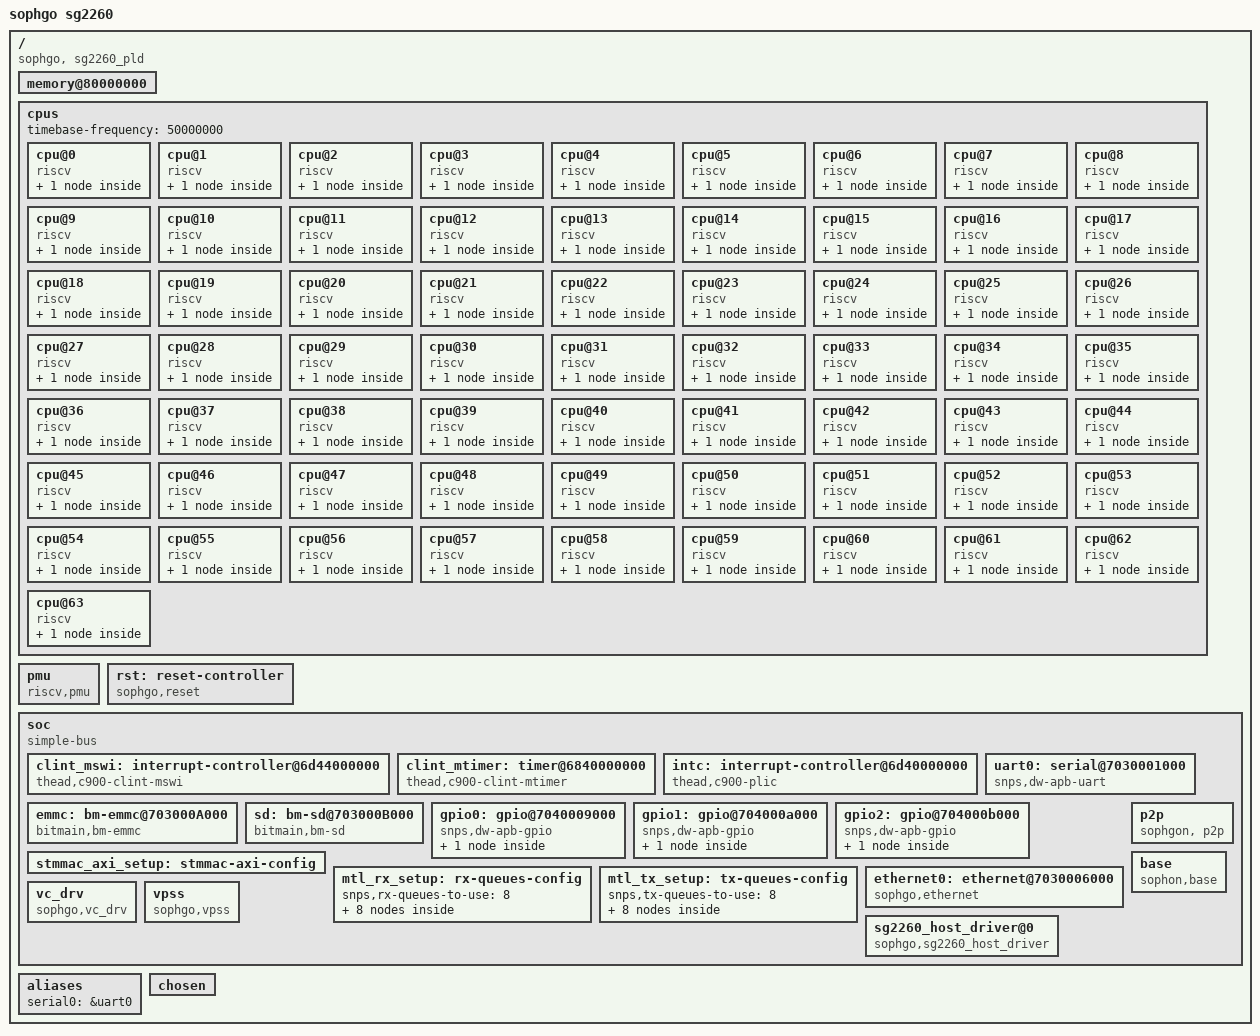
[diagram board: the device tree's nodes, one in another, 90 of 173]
// SPDX-License-Identifier: (GPL-2.0 OR MIT)
/*
 * Copyright (C) 2022 Sophgo Technology Inc. All rights reserved.
 */

/dts-v1/;
#include <dt-bindings/interrupt-controller/irq.h>
#include <dt-bindings/clock/sophgo,sg2044-clock.h>
#include <dt-bindings/reset/sophgo,sg2044-reset.h>
#include "sg2044-clock.dtsi"
#include "sg2044-pinctrl.dtsi"

/ {
	model = "sophgo sg2260";
	compatible = "sophgo, sg2260_pld";
	#address-cells = <2>;
	#size-cells = <2>;
	dma-noncoherent;

	memory@80000000 {
		device_type = "memory";
		reg = <0x00000000 0x80000000 0x00000010 0x00000000>;
	};

	cpus {
		#address-cells = <1>;
		#size-cells = <0>;
		timebase-frequency = <50000000>;
		cpu@0 {
			device_type = "cpu";
			reg = <0>;
			status = "okay";
			compatible = "riscv";
			riscv,isa = "rv64imafdcv_zicbom_zicbop_zicboz_zicond1p0_zihintntl0p2_zihintpause_zawrs_zfa0p1_zfbfmin0p8_zfh_zca_zcb_zcd_zba_zbb_zbc_zbs_zvfbfmin0p8_zvfbfwma0p8_zvfh0p1_sscofpmf_sstc_svinval_svnapot_svpbmt";
			riscv,cbom-block-size = <64>;
			riscv,cboz-block-size = <64>;
			mmu-type = "riscv,sv48";
			cpu0_intc: interrupt-controller {
				#interrupt-cells = <1>;
				compatible = "riscv,cpu-intc";
				interrupt-controller;
			};
		};
		cpu@1 {
			device_type = "cpu";
			reg = <1>;
			status = "okay";
			compatible = "riscv";
			riscv,isa = "rv64imafdcv_zicbom_zicbop_zicboz_zicond1p0_zihintntl0p2_zihintpause_zawrs_zfa0p1_zfbfmin0p8_zfh_zca_zcb_zcd_zba_zbb_zbc_zbs_zvfbfmin0p8_zvfbfwma0p8_zvfh0p1_sscofpmf_sstc_svinval_svnapot_svpbmt";
			riscv,cbom-block-size = <64>;
			riscv,cboz-block-size = <64>;
			mmu-type = "riscv,sv48";
			cpu1_intc: interrupt-controller {
				#interrupt-cells = <1>;
				compatible = "riscv,cpu-intc";
				interrupt-controller;
			};
		};
		cpu@2 {
			device_type = "cpu";
			reg = <2>;
			status = "okay";
			compatible = "riscv";
			riscv,isa = "rv64imafdcv_zicbom_zicbop_zicboz_zicond1p0_zihintntl0p2_zihintpause_zawrs_zfa0p1_zfbfmin0p8_zfh_zca_zcb_zcd_zba_zbb_zbc_zbs_zvfbfmin0p8_zvfbfwma0p8_zvfh0p1_sscofpmf_sstc_svinval_svnapot_svpbmt";
			riscv,cbom-block-size = <64>;
			riscv,cboz-block-size = <64>;
			mmu-type = "riscv,sv48";
			cpu2_intc: interrupt-controller {
				#interrupt-cells = <1>;
				compatible = "riscv,cpu-intc";
				interrupt-controller;
			};
		};
		cpu@3 {
			device_type = "cpu";
			reg = <3>;
			status = "okay";
			compatible = "riscv";
			riscv,isa = "rv64imafdcv_zicbom_zicbop_zicboz_zicond1p0_zihintntl0p2_zihintpause_zawrs_zfa0p1_zfbfmin0p8_zfh_zca_zcb_zcd_zba_zbb_zbc_zbs_zvfbfmin0p8_zvfbfwma0p8_zvfh0p1_sscofpmf_sstc_svinval_svnapot_svpbmt";
			riscv,cbom-block-size = <64>;
			riscv,cboz-block-size = <64>;
			mmu-type = "riscv,sv48";
			cpu3_intc: interrupt-controller {
				#interrupt-cells = <1>;
				compatible = "riscv,cpu-intc";
				interrupt-controller;
			};
		};
		cpu@4 {
			device_type = "cpu";
			reg = <4>;
			status = "okay";
			compatible = "riscv";
			riscv,isa = "rv64imafdcv_zicbom_zicbop_zicboz_zicond1p0_zihintntl0p2_zihintpause_zawrs_zfa0p1_zfbfmin0p8_zfh_zca_zcb_zcd_zba_zbb_zbc_zbs_zvfbfmin0p8_zvfbfwma0p8_zvfh0p1_sscofpmf_sstc_svinval_svnapot_svpbmt";
			riscv,cbom-block-size = <64>;
			riscv,cboz-block-size = <64>;
			mmu-type = "riscv,sv48";
			cpu4_intc: interrupt-controller {
				#interrupt-cells = <1>;
				compatible = "riscv,cpu-intc";
				interrupt-controller;
			};
		};
		cpu@5 {
			device_type = "cpu";
			reg = <5>;
			status = "okay";
			compatible = "riscv";
			riscv,isa = "rv64imafdcv_zicbom_zicbop_zicboz_zicond1p0_zihintntl0p2_zihintpause_zawrs_zfa0p1_zfbfmin0p8_zfh_zca_zcb_zcd_zba_zbb_zbc_zbs_zvfbfmin0p8_zvfbfwma0p8_zvfh0p1_sscofpmf_sstc_svinval_svnapot_svpbmt";
			riscv,cbom-block-size = <64>;
			riscv,cboz-block-size = <64>;
			mmu-type = "riscv,sv48";
			cpu5_intc: interrupt-controller {
				#interrupt-cells = <1>;
				compatible = "riscv,cpu-intc";
				interrupt-controller;
			};
		};
		cpu@6 {
			device_type = "cpu";
			reg = <6>;
			status = "okay";
			compatible = "riscv";
			riscv,isa = "rv64imafdcv_zicbom_zicbop_zicboz_zicond1p0_zihintntl0p2_zihintpause_zawrs_zfa0p1_zfbfmin0p8_zfh_zca_zcb_zcd_zba_zbb_zbc_zbs_zvfbfmin0p8_zvfbfwma0p8_zvfh0p1_sscofpmf_sstc_svinval_svnapot_svpbmt";
			riscv,cbom-block-size = <64>;
			riscv,cboz-block-size = <64>;
			mmu-type = "riscv,sv48";
			cpu6_intc: interrupt-controller {
				#interrupt-cells = <1>;
				compatible = "riscv,cpu-intc";
				interrupt-controller;
			};
		};
		cpu@7 {
			device_type = "cpu";
			reg = <7>;
			status = "okay";
			compatible = "riscv";
			riscv,isa = "rv64imafdcv_zicbom_zicbop_zicboz_zicond1p0_zihintntl0p2_zihintpause_zawrs_zfa0p1_zfbfmin0p8_zfh_zca_zcb_zcd_zba_zbb_zbc_zbs_zvfbfmin0p8_zvfbfwma0p8_zvfh0p1_sscofpmf_sstc_svinval_svnapot_svpbmt";
			riscv,cbom-block-size = <64>;
			riscv,cboz-block-size = <64>;
			mmu-type = "riscv,sv48";
			cpu7_intc: interrupt-controller {
				#interrupt-cells = <1>;
				compatible = "riscv,cpu-intc";
				interrupt-controller;
			};
		};
		cpu@8 {
			device_type = "cpu";
			reg = <8>;
			status = "okay";
			compatible = "riscv";
			riscv,isa = "rv64imafdcv_zicbom_zicbop_zicboz_zicond1p0_zihintntl0p2_zihintpause_zawrs_zfa0p1_zfbfmin0p8_zfh_zca_zcb_zcd_zba_zbb_zbc_zbs_zvfbfmin0p8_zvfbfwma0p8_zvfh0p1_sscofpmf_sstc_svinval_svnapot_svpbmt";
			riscv,cbom-block-size = <64>;
			riscv,cboz-block-size = <64>;
			mmu-type = "riscv,sv48";
			cpu8_intc: interrupt-controller {
				#interrupt-cells = <1>;
				compatible = "riscv,cpu-intc";
				interrupt-controller;
			};
		};
		cpu@9 {
			device_type = "cpu";
			reg = <9>;
			status = "okay";
			compatible = "riscv";
			riscv,isa = "rv64imafdcv_zicbom_zicbop_zicboz_zicond1p0_zihintntl0p2_zihintpause_zawrs_zfa0p1_zfbfmin0p8_zfh_zca_zcb_zcd_zba_zbb_zbc_zbs_zvfbfmin0p8_zvfbfwma0p8_zvfh0p1_sscofpmf_sstc_svinval_svnapot_svpbmt";
			riscv,cbom-block-size = <64>;
			riscv,cboz-block-size = <64>;
			mmu-type = "riscv,sv48";
			cpu9_intc: interrupt-controller {
				#interrupt-cells = <1>;
				compatible = "riscv,cpu-intc";
				interrupt-controller;
			};
		};
		cpu@10 {
			device_type = "cpu";
			reg = <10>;
			status = "okay";
			compatible = "riscv";
			riscv,isa = "rv64imafdcv_zicbom_zicbop_zicboz_zicond1p0_zihintntl0p2_zihintpause_zawrs_zfa0p1_zfbfmin0p8_zfh_zca_zcb_zcd_zba_zbb_zbc_zbs_zvfbfmin0p8_zvfbfwma0p8_zvfh0p1_sscofpmf_sstc_svinval_svnapot_svpbmt";
			riscv,cbom-block-size = <64>;
			riscv,cboz-block-size = <64>;
			mmu-type = "riscv,sv48";
			cpu10_intc: interrupt-controller {
				#interrupt-cells = <1>;
				compatible = "riscv,cpu-intc";
				interrupt-controller;
			};
		};
		cpu@11 {
			device_type = "cpu";
			reg = <11>;
			status = "okay";
			compatible = "riscv";
			riscv,isa = "rv64imafdcv_zicbom_zicbop_zicboz_zicond1p0_zihintntl0p2_zihintpause_zawrs_zfa0p1_zfbfmin0p8_zfh_zca_zcb_zcd_zba_zbb_zbc_zbs_zvfbfmin0p8_zvfbfwma0p8_zvfh0p1_sscofpmf_sstc_svinval_svnapot_svpbmt";
			riscv,cbom-block-size = <64>;
			riscv,cboz-block-size = <64>;
			mmu-type = "riscv,sv48";
			cpu11_intc: interrupt-controller {
				#interrupt-cells = <1>;
				compatible = "riscv,cpu-intc";
				interrupt-controller;
			};
		};
		cpu@12 {
			device_type = "cpu";
			reg = <12>;
			status = "okay";
			compatible = "riscv";
			riscv,isa = "rv64imafdcv_zicbom_zicbop_zicboz_zicond1p0_zihintntl0p2_zihintpause_zawrs_zfa0p1_zfbfmin0p8_zfh_zca_zcb_zcd_zba_zbb_zbc_zbs_zvfbfmin0p8_zvfbfwma0p8_zvfh0p1_sscofpmf_sstc_svinval_svnapot_svpbmt";
			riscv,cbom-block-size = <64>;
			riscv,cboz-block-size = <64>;
			mmu-type = "riscv,sv48";
			cpu12_intc: interrupt-controller {
				#interrupt-cells = <1>;
				compatible = "riscv,cpu-intc";
				interrupt-controller;
			};
		};
		cpu@13 {
			device_type = "cpu";
			reg = <13>;
			status = "okay";
			compatible = "riscv";
			riscv,isa = "rv64imafdcv_zicbom_zicbop_zicboz_zicond1p0_zihintntl0p2_zihintpause_zawrs_zfa0p1_zfbfmin0p8_zfh_zca_zcb_zcd_zba_zbb_zbc_zbs_zvfbfmin0p8_zvfbfwma0p8_zvfh0p1_sscofpmf_sstc_svinval_svnapot_svpbmt";
			riscv,cbom-block-size = <64>;
			riscv,cboz-block-size = <64>;
			mmu-type = "riscv,sv48";
			cpu13_intc: interrupt-controller {
				#interrupt-cells = <1>;
				compatible = "riscv,cpu-intc";
				interrupt-controller;
			};
		};
		cpu@14 {
			device_type = "cpu";
			reg = <14>;
			status = "okay";
			compatible = "riscv";
			riscv,isa = "rv64imafdcv_zicbom_zicbop_zicboz_zicond1p0_zihintntl0p2_zihintpause_zawrs_zfa0p1_zfbfmin0p8_zfh_zca_zcb_zcd_zba_zbb_zbc_zbs_zvfbfmin0p8_zvfbfwma0p8_zvfh0p1_sscofpmf_sstc_svinval_svnapot_svpbmt";
			riscv,cbom-block-size = <64>;
			riscv,cboz-block-size = <64>;
			mmu-type = "riscv,sv48";
			cpu14_intc: interrupt-controller {
				#interrupt-cells = <1>;
				compatible = "riscv,cpu-intc";
				interrupt-controller;
			};
		};
		cpu@15 {
			device_type = "cpu";
			reg = <15>;
			status = "okay";
			compatible = "riscv";
			riscv,isa = "rv64imafdcv_zicbom_zicbop_zicboz_zicond1p0_zihintntl0p2_zihintpause_zawrs_zfa0p1_zfbfmin0p8_zfh_zca_zcb_zcd_zba_zbb_zbc_zbs_zvfbfmin0p8_zvfbfwma0p8_zvfh0p1_sscofpmf_sstc_svinval_svnapot_svpbmt";
			riscv,cbom-block-size = <64>;
			riscv,cboz-block-size = <64>;
			mmu-type = "riscv,sv48";
			cpu15_intc: interrupt-controller {
				#interrupt-cells = <1>;
				compatible = "riscv,cpu-intc";
				interrupt-controller;
			};
		};
		cpu@16 {
			device_type = "cpu";
			reg = <16>;
			status = "okay";
			compatible = "riscv";
			riscv,isa = "rv64imafdcv_zicbom_zicbop_zicboz_zicond1p0_zihintntl0p2_zihintpause_zawrs_zfa0p1_zfbfmin0p8_zfh_zca_zcb_zcd_zba_zbb_zbc_zbs_zvfbfmin0p8_zvfbfwma0p8_zvfh0p1_sscofpmf_sstc_svinval_svnapot_svpbmt";
			riscv,cbom-block-size = <64>;
			riscv,cboz-block-size = <64>;
			mmu-type = "riscv,sv48";
			cpu16_intc: interrupt-controller {
				#interrupt-cells = <1>;
				compatible = "riscv,cpu-intc";
				interrupt-controller;
			};
		};
		cpu@17 {
			device_type = "cpu";
			reg = <17>;
			status = "okay";
			compatible = "riscv";
			riscv,isa = "rv64imafdcv_zicbom_zicbop_zicboz_zicond1p0_zihintntl0p2_zihintpause_zawrs_zfa0p1_zfbfmin0p8_zfh_zca_zcb_zcd_zba_zbb_zbc_zbs_zvfbfmin0p8_zvfbfwma0p8_zvfh0p1_sscofpmf_sstc_svinval_svnapot_svpbmt";
			riscv,cbom-block-size = <64>;
			riscv,cboz-block-size = <64>;
			mmu-type = "riscv,sv48";
			cpu17_intc: interrupt-controller {
				#interrupt-cells = <1>;
				compatible = "riscv,cpu-intc";
				interrupt-controller;
			};
		};
		cpu@18 {
			device_type = "cpu";
			reg = <18>;
			status = "okay";
			compatible = "riscv";
			riscv,isa = "rv64imafdcv_zicbom_zicbop_zicboz_zicond1p0_zihintntl0p2_zihintpause_zawrs_zfa0p1_zfbfmin0p8_zfh_zca_zcb_zcd_zba_zbb_zbc_zbs_zvfbfmin0p8_zvfbfwma0p8_zvfh0p1_sscofpmf_sstc_svinval_svnapot_svpbmt";
			riscv,cbom-block-size = <64>;
			riscv,cboz-block-size = <64>;
			mmu-type = "riscv,sv48";
			cpu18_intc: interrupt-controller {
				#interrupt-cells = <1>;
				compatible = "riscv,cpu-intc";
				interrupt-controller;
			};
		};
		cpu@19 {
			device_type = "cpu";
			reg = <19>;
			status = "okay";
			compatible = "riscv";
			riscv,isa = "rv64imafdcv_zicbom_zicbop_zicboz_zicond1p0_zihintntl0p2_zihintpause_zawrs_zfa0p1_zfbfmin0p8_zfh_zca_zcb_zcd_zba_zbb_zbc_zbs_zvfbfmin0p8_zvfbfwma0p8_zvfh0p1_sscofpmf_sstc_svinval_svnapot_svpbmt";
			riscv,cbom-block-size = <64>;
			riscv,cboz-block-size = <64>;
			mmu-type = "riscv,sv48";
			cpu19_intc: interrupt-controller {
				#interrupt-cells = <1>;
				compatible = "riscv,cpu-intc";
				interrupt-controller;
			};
		};
		cpu@20 {
			device_type = "cpu";
			reg = <20>;
			status = "okay";
			compatible = "riscv";
			riscv,isa = "rv64imafdcv_zicbom_zicbop_zicboz_zicond1p0_zihintntl0p2_zihintpause_zawrs_zfa0p1_zfbfmin0p8_zfh_zca_zcb_zcd_zba_zbb_zbc_zbs_zvfbfmin0p8_zvfbfwma0p8_zvfh0p1_sscofpmf_sstc_svinval_svnapot_svpbmt";
			riscv,cbom-block-size = <64>;
			riscv,cboz-block-size = <64>;
			mmu-type = "riscv,sv48";
			cpu20_intc: interrupt-controller {
				#interrupt-cells = <1>;
				compatible = "riscv,cpu-intc";
				interrupt-controller;
			};
		};
		cpu@21 {
			device_type = "cpu";
			reg = <21>;
			status = "okay";
			compatible = "riscv";
			riscv,isa = "rv64imafdcv_zicbom_zicbop_zicboz_zicond1p0_zihintntl0p2_zihintpause_zawrs_zfa0p1_zfbfmin0p8_zfh_zca_zcb_zcd_zba_zbb_zbc_zbs_zvfbfmin0p8_zvfbfwma0p8_zvfh0p1_sscofpmf_sstc_svinval_svnapot_svpbmt";
			riscv,cbom-block-size = <64>;
			riscv,cboz-block-size = <64>;
			mmu-type = "riscv,sv48";
			cpu21_intc: interrupt-controller {
				#interrupt-cells = <1>;
				compatible = "riscv,cpu-intc";
				interrupt-controller;
			};
		};
		cpu@22 {
			device_type = "cpu";
			reg = <22>;
			status = "okay";
			compatible = "riscv";
			riscv,isa = "rv64imafdcv_zicbom_zicbop_zicboz_zicond1p0_zihintntl0p2_zihintpause_zawrs_zfa0p1_zfbfmin0p8_zfh_zca_zcb_zcd_zba_zbb_zbc_zbs_zvfbfmin0p8_zvfbfwma0p8_zvfh0p1_sscofpmf_sstc_svinval_svnapot_svpbmt";
			riscv,cbom-block-size = <64>;
			riscv,cboz-block-size = <64>;
			mmu-type = "riscv,sv48";
			cpu22_intc: interrupt-controller {
				#interrupt-cells = <1>;
				compatible = "riscv,cpu-intc";
				interrupt-controller;
			};
		};
		cpu@23 {
			device_type = "cpu";
			reg = <23>;
			status = "okay";
			compatible = "riscv";
			riscv,isa = "rv64imafdcv_zicbom_zicbop_zicboz_zicond1p0_zihintntl0p2_zihintpause_zawrs_zfa0p1_zfbfmin0p8_zfh_zca_zcb_zcd_zba_zbb_zbc_zbs_zvfbfmin0p8_zvfbfwma0p8_zvfh0p1_sscofpmf_sstc_svinval_svnapot_svpbmt";
			riscv,cbom-block-size = <64>;
			riscv,cboz-block-size = <64>;
			mmu-type = "riscv,sv48";
			cpu23_intc: interrupt-controller {
				#interrupt-cells = <1>;
				compatible = "riscv,cpu-intc";
				interrupt-controller;
			};
		};
		cpu@24 {
			device_type = "cpu";
			reg = <24>;
			status = "okay";
			compatible = "riscv";
			riscv,isa = "rv64imafdcv_zicbom_zicbop_zicboz_zicond1p0_zihintntl0p2_zihintpause_zawrs_zfa0p1_zfbfmin0p8_zfh_zca_zcb_zcd_zba_zbb_zbc_zbs_zvfbfmin0p8_zvfbfwma0p8_zvfh0p1_sscofpmf_sstc_svinval_svnapot_svpbmt";
			riscv,cbom-block-size = <64>;
			riscv,cboz-block-size = <64>;
			mmu-type = "riscv,sv48";
			cpu24_intc: interrupt-controller {
				#interrupt-cells = <1>;
				compatible = "riscv,cpu-intc";
				interrupt-controller;
			};
		};
		cpu@25 {
			device_type = "cpu";
			reg = <25>;
			status = "okay";
			compatible = "riscv";
			riscv,isa = "rv64imafdcv_zicbom_zicbop_zicboz_zicond1p0_zihintntl0p2_zihintpause_zawrs_zfa0p1_zfbfmin0p8_zfh_zca_zcb_zcd_zba_zbb_zbc_zbs_zvfbfmin0p8_zvfbfwma0p8_zvfh0p1_sscofpmf_sstc_svinval_svnapot_svpbmt";
			riscv,cbom-block-size = <64>;
			riscv,cboz-block-size = <64>;
			mmu-type = "riscv,sv48";
			cpu25_intc: interrupt-controller {
				#interrupt-cells = <1>;
				compatible = "riscv,cpu-intc";
				interrupt-controller;
			};
		};
		cpu@26 {
			device_type = "cpu";
			reg = <26>;
			status = "okay";
			compatible = "riscv";
			riscv,isa = "rv64imafdcv_zicbom_zicbop_zicboz_zicond1p0_zihintntl0p2_zihintpause_zawrs_zfa0p1_zfbfmin0p8_zfh_zca_zcb_zcd_zba_zbb_zbc_zbs_zvfbfmin0p8_zvfbfwma0p8_zvfh0p1_sscofpmf_sstc_svinval_svnapot_svpbmt";
			riscv,cbom-block-size = <64>;
			riscv,cboz-block-size = <64>;
			mmu-type = "riscv,sv48";
			cpu26_intc: interrupt-controller {
				#interrupt-cells = <1>;
				compatible = "riscv,cpu-intc";
				interrupt-controller;
			};
		};
		cpu@27 {
			device_type = "cpu";
			reg = <27>;
			status = "okay";
			compatible = "riscv";
			riscv,isa = "rv64imafdcv_zicbom_zicbop_zicboz_zicond1p0_zihintntl0p2_zihintpause_zawrs_zfa0p1_zfbfmin0p8_zfh_zca_zcb_zcd_zba_zbb_zbc_zbs_zvfbfmin0p8_zvfbfwma0p8_zvfh0p1_sscofpmf_sstc_svinval_svnapot_svpbmt";
			riscv,cbom-block-size = <64>;
			riscv,cboz-block-size = <64>;
			mmu-type = "riscv,sv48";
			cpu27_intc: interrupt-controller {
				#interrupt-cells = <1>;
				compatible = "riscv,cpu-intc";
				interrupt-controller;
			};
		};
		cpu@28 {
			device_type = "cpu";
			reg = <28>;
			status = "okay";
			compatible = "riscv";
			riscv,isa = "rv64imafdcv_zicbom_zicbop_zicboz_zicond1p0_zihintntl0p2_zihintpause_zawrs_zfa0p1_zfbfmin0p8_zfh_zca_zcb_zcd_zba_zbb_zbc_zbs_zvfbfmin0p8_zvfbfwma0p8_zvfh0p1_sscofpmf_sstc_svinval_svnapot_svpbmt";
			riscv,cbom-block-size = <64>;
			riscv,cboz-block-size = <64>;
			mmu-type = "riscv,sv48";
			cpu28_intc: interrupt-controller {
				#interrupt-cells = <1>;
				compatible = "riscv,cpu-intc";
				interrupt-controller;
			};
		};
		cpu@29 {
			device_type = "cpu";
			reg = <29>;
			status = "okay";
			compatible = "riscv";
			riscv,isa = "rv64imafdcv_zicbom_zicbop_zicboz_zicond1p0_zihintntl0p2_zihintpause_zawrs_zfa0p1_zfbfmin0p8_zfh_zca_zcb_zcd_zba_zbb_zbc_zbs_zvfbfmin0p8_zvfbfwma0p8_zvfh0p1_sscofpmf_sstc_svinval_svnapot_svpbmt";
			riscv,cbom-block-size = <64>;
			riscv,cboz-block-size = <64>;
			mmu-type = "riscv,sv48";
			cpu29_intc: interrupt-controller {
				#interrupt-cells = <1>;
				compatible = "riscv,cpu-intc";
				interrupt-controller;
			};
		};
		cpu@30 {
			device_type = "cpu";
			reg = <30>;
			status = "okay";
			compatible = "riscv";
			riscv,isa = "rv64imafdcv_zicbom_zicbop_zicboz_zicond1p0_zihintntl0p2_zihintpause_zawrs_zfa0p1_zfbfmin0p8_zfh_zca_zcb_zcd_zba_zbb_zbc_zbs_zvfbfmin0p8_zvfbfwma0p8_zvfh0p1_sscofpmf_sstc_svinval_svnapot_svpbmt";
			riscv,cbom-block-size = <64>;
			riscv,cboz-block-size = <64>;
			mmu-type = "riscv,sv48";
			cpu30_intc: interrupt-controller {
				#interrupt-cells = <1>;
				compatible = "riscv,cpu-intc";
				interrupt-controller;
			};
		};
		cpu@31 {
			device_type = "cpu";
			reg = <31>;
			status = "okay";
			compatible = "riscv";
			riscv,isa = "rv64imafdcv_zicbom_zicbop_zicboz_zicond1p0_zihintntl0p2_zihintpause_zawrs_zfa0p1_zfbfmin0p8_zfh_zca_zcb_zcd_zba_zbb_zbc_zbs_zvfbfmin0p8_zvfbfwma0p8_zvfh0p1_sscofpmf_sstc_svinval_svnapot_svpbmt";
			riscv,cbom-block-size = <64>;
			riscv,cboz-block-size = <64>;
			mmu-type = "riscv,sv48";
			cpu31_intc: interrupt-controller {
				#interrupt-cells = <1>;
				compatible = "riscv,cpu-intc";
				interrupt-controller;
			};
		};
		cpu@32 {
			device_type = "cpu";
			reg = <32>;
			status = "okay";
			compatible = "riscv";
			riscv,isa = "rv64imafdcv_zicbom_zicbop_zicboz_zicond1p0_zihintntl0p2_zihintpause_zawrs_zfa0p1_zfbfmin0p8_zfh_zca_zcb_zcd_zba_zbb_zbc_zbs_zvfbfmin0p8_zvfbfwma0p8_zvfh0p1_sscofpmf_sstc_svinval_svnapot_svpbmt";
			riscv,cbom-block-size = <64>;
			riscv,cboz-block-size = <64>;
			mmu-type = "riscv,sv48";
			cpu32_intc: interrupt-controller {
				#interrupt-cells = <1>;
				compatible = "riscv,cpu-intc";
				interrupt-controller;
			};
		};
		cpu@33 {
			device_type = "cpu";
			reg = <33>;
			status = "okay";
			compatible = "riscv";
			riscv,isa = "rv64imafdcv_zicbom_zicbop_zicboz_zicond1p0_zihintntl0p2_zihintpause_zawrs_zfa0p1_zfbfmin0p8_zfh_zca_zcb_zcd_zba_zbb_zbc_zbs_zvfbfmin0p8_zvfbfwma0p8_zvfh0p1_sscofpmf_sstc_svinval_svnapot_svpbmt";
			riscv,cbom-block-size = <64>;
			riscv,cboz-block-size = <64>;
			mmu-type = "riscv,sv48";
			cpu33_intc: interrupt-controller {
				#interrupt-cells = <1>;
				compatible = "riscv,cpu-intc";
				interrupt-controller;
			};
		};
		cpu@34 {
			device_type = "cpu";
			reg = <34>;
			status = "okay";
			compatible = "riscv";
			riscv,isa = "rv64imafdcv_zicbom_zicbop_zicboz_zicond1p0_zihintntl0p2_zihintpause_zawrs_zfa0p1_zfbfmin0p8_zfh_zca_zcb_zcd_zba_zbb_zbc_zbs_zvfbfmin0p8_zvfbfwma0p8_zvfh0p1_sscofpmf_sstc_svinval_svnapot_svpbmt";
			riscv,cbom-block-size = <64>;
			riscv,cboz-block-size = <64>;
			mmu-type = "riscv,sv48";
			cpu34_intc: interrupt-controller {
				#interrupt-cells = <1>;
				compatible = "riscv,cpu-intc";
				interrupt-controller;
			};
		};
		cpu@35 {
			device_type = "cpu";
			reg = <35>;
			status = "okay";
			compatible = "riscv";
			riscv,isa = "rv64imafdcv_zicbom_zicbop_zicboz_zicond1p0_zihintntl0p2_zihintpause_zawrs_zfa0p1_zfbfmin0p8_zfh_zca_zcb_zcd_zba_zbb_zbc_zbs_zvfbfmin0p8_zvfbfwma0p8_zvfh0p1_sscofpmf_sstc_svinval_svnapot_svpbmt";
			riscv,cbom-block-size = <64>;
			riscv,cboz-block-size = <64>;
			mmu-type = "riscv,sv48";
			cpu35_intc: interrupt-controller {
				#interrupt-cells = <1>;
				compatible = "riscv,cpu-intc";
				interrupt-controller;
			};
		};
		cpu@36 {
			device_type = "cpu";
			reg = <36>;
			status = "okay";
			compatible = "riscv";
			riscv,isa = "rv64imafdcv_zicbom_zicbop_zicboz_zicond1p0_zihintntl0p2_zihintpause_zawrs_zfa0p1_zfbfmin0p8_zfh_zca_zcb_zcd_zba_zbb_zbc_zbs_zvfbfmin0p8_zvfbfwma0p8_zvfh0p1_sscofpmf_sstc_svinval_svnapot_svpbmt";
			riscv,cbom-block-size = <64>;
			riscv,cboz-block-size = <64>;
			mmu-type = "riscv,sv48";
			cpu36_intc: interrupt-controller {
				#interrupt-cells = <1>;
				compatible = "riscv,cpu-intc";
				interrupt-controller;
			};
		};
		cpu@37 {
			device_type = "cpu";
			reg = <37>;
			status = "okay";
			compatible = "riscv";
			riscv,isa = "rv64imafdcv_zicbom_zicbop_zicboz_zicond1p0_zihintntl0p2_zihintpause_zawrs_zfa0p1_zfbfmin0p8_zfh_zca_zcb_zcd_zba_zbb_zbc_zbs_zvfbfmin0p8_zvfbfwma0p8_zvfh0p1_sscofpmf_sstc_svinval_svnapot_svpbmt";
			riscv,cbom-block-size = <64>;
			riscv,cboz-block-size = <64>;
			mmu-type = "riscv,sv48";
			cpu37_intc: interrupt-controller {
				#interrupt-cells = <1>;
				compatible = "riscv,cpu-intc";
				interrupt-controller;
			};
		};
		cpu@38 {
			device_type = "cpu";
			reg = <38>;
			status = "okay";
			compatible = "riscv";
			riscv,isa = "rv64imafdcv_zicbom_zicbop_zicboz_zicond1p0_zihintntl0p2_zihintpause_zawrs_zfa0p1_zfbfmin0p8_zfh_zca_zcb_zcd_zba_zbb_zbc_zbs_zvfbfmin0p8_zvfbfwma0p8_zvfh0p1_sscofpmf_sstc_svinval_svnapot_svpbmt";
			riscv,cbom-block-size = <64>;
			riscv,cboz-block-size = <64>;
			mmu-type = "riscv,sv48";
			cpu38_intc: interrupt-controller {
				#interrupt-cells = <1>;
				compatible = "riscv,cpu-intc";
				interrupt-controller;
			};
		};
		cpu@39 {
			device_type = "cpu";
			reg = <39>;
			status = "okay";
			compatible = "riscv";
			riscv,isa = "rv64imafdcv_zicbom_zicbop_zicboz_zicond1p0_zihintntl0p2_zihintpause_zawrs_zfa0p1_zfbfmin0p8_zfh_zca_zcb_zcd_zba_zbb_zbc_zbs_zvfbfmin0p8_zvfbfwma0p8_zvfh0p1_sscofpmf_sstc_svinval_svnapot_svpbmt";
			riscv,cbom-block-size = <64>;
			riscv,cboz-block-size = <64>;
			mmu-type = "riscv,sv48";
			cpu39_intc: interrupt-controller {
				#interrupt-cells = <1>;
				compatible = "riscv,cpu-intc";
				interrupt-controller;
			};
		};
		cpu@40 {
			device_type = "cpu";
			reg = <40>;
			status = "okay";
			compatible = "riscv";
			riscv,isa = "rv64imafdcv_zicbom_zicbop_zicboz_zicond1p0_zihintntl0p2_zihintpause_zawrs_zfa0p1_zfbfmin0p8_zfh_zca_zcb_zcd_zba_zbb_zbc_zbs_zvfbfmin0p8_zvfbfwma0p8_zvfh0p1_sscofpmf_sstc_svinval_svnapot_svpbmt";
			riscv,cbom-block-size = <64>;
			riscv,cboz-block-size = <64>;
			mmu-type = "riscv,sv48";
			cpu40_intc: interrupt-controller {
				#interrupt-cells = <1>;
				compatible = "riscv,cpu-intc";
				interrupt-controller;
			};
		};
		cpu@41 {
			device_type = "cpu";
			reg = <41>;
			status = "okay";
			compatible = "riscv";
			riscv,isa = "rv64imafdcv_zicbom_zicbop_zicboz_zicond1p0_zihintntl0p2_zihintpause_zawrs_zfa0p1_zfbfmin0p8_zfh_zca_zcb_zcd_zba_zbb_zbc_zbs_zvfbfmin0p8_zvfbfwma0p8_zvfh0p1_sscofpmf_sstc_svinval_svnapot_svpbmt";
			riscv,cbom-block-size = <64>;
			riscv,cboz-block-size = <64>;
			mmu-type = "riscv,sv48";
			cpu41_intc: interrupt-controller {
				#interrupt-cells = <1>;
				compatible = "riscv,cpu-intc";
				interrupt-controller;
			};
		};
		cpu@42 {
			device_type = "cpu";
			reg = <42>;
			status = "okay";
			compatible = "riscv";
			riscv,isa = "rv64imafdcv_zicbom_zicbop_zicboz_zicond1p0_zihintntl0p2_zihintpause_zawrs_zfa0p1_zfbfmin0p8_zfh_zca_zcb_zcd_zba_zbb_zbc_zbs_zvfbfmin0p8_zvfbfwma0p8_zvfh0p1_sscofpmf_sstc_svinval_svnapot_svpbmt";
			riscv,cbom-block-size = <64>;
			riscv,cboz-block-size = <64>;
			mmu-type = "riscv,sv48";
			cpu42_intc: interrupt-controller {
				#interrupt-cells = <1>;
				compatible = "riscv,cpu-intc";
				interrupt-controller;
			};
		};
		cpu@43 {
			device_type = "cpu";
			reg = <43>;
			status = "okay";
			compatible = "riscv";
			riscv,isa = "rv64imafdcv_zicbom_zicbop_zicboz_zicond1p0_zihintntl0p2_zihintpause_zawrs_zfa0p1_zfbfmin0p8_zfh_zca_zcb_zcd_zba_zbb_zbc_zbs_zvfbfmin0p8_zvfbfwma0p8_zvfh0p1_sscofpmf_sstc_svinval_svnapot_svpbmt";
			riscv,cbom-block-size = <64>;
			riscv,cboz-block-size = <64>;
			mmu-type = "riscv,sv48";
			cpu43_intc: interrupt-controller {
				#interrupt-cells = <1>;
				compatible = "riscv,cpu-intc";
				interrupt-controller;
			};
		};
		cpu@44 {
			device_type = "cpu";
			reg = <44>;
			status = "okay";
			compatible = "riscv";
			riscv,isa = "rv64imafdcv_zicbom_zicbop_zicboz_zicond1p0_zihintntl0p2_zihintpause_zawrs_zfa0p1_zfbfmin0p8_zfh_zca_zcb_zcd_zba_zbb_zbc_zbs_zvfbfmin0p8_zvfbfwma0p8_zvfh0p1_sscofpmf_sstc_svinval_svnapot_svpbmt";
			riscv,cbom-block-size = <64>;
			riscv,cboz-block-size = <64>;
			mmu-type = "riscv,sv48";
			cpu44_intc: interrupt-controller {
				#interrupt-cells = <1>;
				compatible = "riscv,cpu-intc";
				interrupt-controller;
			};
		};
		cpu@45 {
			device_type = "cpu";
			reg = <45>;
			status = "okay";
			compatible = "riscv";
			riscv,isa = "rv64imafdcv_zicbom_zicbop_zicboz_zicond1p0_zihintntl0p2_zihintpause_zawrs_zfa0p1_zfbfmin0p8_zfh_zca_zcb_zcd_zba_zbb_zbc_zbs_zvfbfmin0p8_zvfbfwma0p8_zvfh0p1_sscofpmf_sstc_svinval_svnapot_svpbmt";
			riscv,cbom-block-size = <64>;
			riscv,cboz-block-size = <64>;
			mmu-type = "riscv,sv48";
			cpu45_intc: interrupt-controller {
				#interrupt-cells = <1>;
				compatible = "riscv,cpu-intc";
				interrupt-controller;
			};
		};
		cpu@46 {
			device_type = "cpu";
			reg = <46>;
			status = "okay";
			compatible = "riscv";
			riscv,isa = "rv64imafdcv_zicbom_zicbop_zicboz_zicond1p0_zihintntl0p2_zihintpause_zawrs_zfa0p1_zfbfmin0p8_zfh_zca_zcb_zcd_zba_zbb_zbc_zbs_zvfbfmin0p8_zvfbfwma0p8_zvfh0p1_sscofpmf_sstc_svinval_svnapot_svpbmt";
			riscv,cbom-block-size = <64>;
			riscv,cboz-block-size = <64>;
			mmu-type = "riscv,sv48";
			cpu46_intc: interrupt-controller {
				#interrupt-cells = <1>;
				compatible = "riscv,cpu-intc";
				interrupt-controller;
			};
		};
		cpu@47 {
			device_type = "cpu";
			reg = <47>;
			status = "okay";
			compatible = "riscv";
			riscv,isa = "rv64imafdcv_zicbom_zicbop_zicboz_zicond1p0_zihintntl0p2_zihintpause_zawrs_zfa0p1_zfbfmin0p8_zfh_zca_zcb_zcd_zba_zbb_zbc_zbs_zvfbfmin0p8_zvfbfwma0p8_zvfh0p1_sscofpmf_sstc_svinval_svnapot_svpbmt";
			riscv,cbom-block-size = <64>;
			riscv,cboz-block-size = <64>;
			mmu-type = "riscv,sv48";
			cpu47_intc: interrupt-controller {
				#interrupt-cells = <1>;
				compatible = "riscv,cpu-intc";
				interrupt-controller;
			};
		};
		cpu@48 {
			device_type = "cpu";
			reg = <48>;
			status = "okay";
			compatible = "riscv";
			riscv,isa = "rv64imafdcv_zicbom_zicbop_zicboz_zicond1p0_zihintntl0p2_zihintpause_zawrs_zfa0p1_zfbfmin0p8_zfh_zca_zcb_zcd_zba_zbb_zbc_zbs_zvfbfmin0p8_zvfbfwma0p8_zvfh0p1_sscofpmf_sstc_svinval_svnapot_svpbmt";
			riscv,cbom-block-size = <64>;
			riscv,cboz-block-size = <64>;
			mmu-type = "riscv,sv48";
			cpu48_intc: interrupt-controller {
				#interrupt-cells = <1>;
				compatible = "riscv,cpu-intc";
				interrupt-controller;
			};
		};
		cpu@49 {
			device_type = "cpu";
			reg = <49>;
			status = "okay";
			compatible = "riscv";
			riscv,isa = "rv64imafdcv_zicbom_zicbop_zicboz_zicond1p0_zihintntl0p2_zihintpause_zawrs_zfa0p1_zfbfmin0p8_zfh_zca_zcb_zcd_zba_zbb_zbc_zbs_zvfbfmin0p8_zvfbfwma0p8_zvfh0p1_sscofpmf_sstc_svinval_svnapot_svpbmt";
			riscv,cbom-block-size = <64>;
			riscv,cboz-block-size = <64>;
			mmu-type = "riscv,sv48";
			cpu49_intc: interrupt-controller {
				#interrupt-cells = <1>;
				compatible = "riscv,cpu-intc";
				interrupt-controller;
			};
		};
		cpu@50 {
			device_type = "cpu";
			reg = <50>;
			status = "okay";
			compatible = "riscv";
			riscv,isa = "rv64imafdcv_zicbom_zicbop_zicboz_zicond1p0_zihintntl0p2_zihintpause_zawrs_zfa0p1_zfbfmin0p8_zfh_zca_zcb_zcd_zba_zbb_zbc_zbs_zvfbfmin0p8_zvfbfwma0p8_zvfh0p1_sscofpmf_sstc_svinval_svnapot_svpbmt";
			riscv,cbom-block-size = <64>;
			riscv,cboz-block-size = <64>;
			mmu-type = "riscv,sv48";
			cpu50_intc: interrupt-controller {
				#interrupt-cells = <1>;
				compatible = "riscv,cpu-intc";
				interrupt-controller;
			};
		};
		cpu@51 {
			device_type = "cpu";
			reg = <51>;
			status = "okay";
			compatible = "riscv";
			riscv,isa = "rv64imafdcv_zicbom_zicbop_zicboz_zicond1p0_zihintntl0p2_zihintpause_zawrs_zfa0p1_zfbfmin0p8_zfh_zca_zcb_zcd_zba_zbb_zbc_zbs_zvfbfmin0p8_zvfbfwma0p8_zvfh0p1_sscofpmf_sstc_svinval_svnapot_svpbmt";
			riscv,cbom-block-size = <64>;
			riscv,cboz-block-size = <64>;
			mmu-type = "riscv,sv48";
			cpu51_intc: interrupt-controller {
				#interrupt-cells = <1>;
				compatible = "riscv,cpu-intc";
				interrupt-controller;
			};
		};
		cpu@52 {
			device_type = "cpu";
			reg = <52>;
			status = "okay";
			compatible = "riscv";
			riscv,isa = "rv64imafdcv_zicbom_zicbop_zicboz_zicond1p0_zihintntl0p2_zihintpause_zawrs_zfa0p1_zfbfmin0p8_zfh_zca_zcb_zcd_zba_zbb_zbc_zbs_zvfbfmin0p8_zvfbfwma0p8_zvfh0p1_sscofpmf_sstc_svinval_svnapot_svpbmt";
			riscv,cbom-block-size = <64>;
			riscv,cboz-block-size = <64>;
			mmu-type = "riscv,sv48";
			cpu52_intc: interrupt-controller {
				#interrupt-cells = <1>;
				compatible = "riscv,cpu-intc";
				interrupt-controller;
			};
		};
		cpu@53 {
			device_type = "cpu";
			reg = <53>;
			status = "okay";
			compatible = "riscv";
			riscv,isa = "rv64imafdcv_zicbom_zicbop_zicboz_zicond1p0_zihintntl0p2_zihintpause_zawrs_zfa0p1_zfbfmin0p8_zfh_zca_zcb_zcd_zba_zbb_zbc_zbs_zvfbfmin0p8_zvfbfwma0p8_zvfh0p1_sscofpmf_sstc_svinval_svnapot_svpbmt";
			riscv,cbom-block-size = <64>;
			riscv,cboz-block-size = <64>;
			mmu-type = "riscv,sv48";
			cpu53_intc: interrupt-controller {
				#interrupt-cells = <1>;
				compatible = "riscv,cpu-intc";
				interrupt-controller;
			};
		};
		cpu@54 {
			device_type = "cpu";
			reg = <54>;
			status = "okay";
			compatible = "riscv";
			riscv,isa = "rv64imafdcv_zicbom_zicbop_zicboz_zicond1p0_zihintntl0p2_zihintpause_zawrs_zfa0p1_zfbfmin0p8_zfh_zca_zcb_zcd_zba_zbb_zbc_zbs_zvfbfmin0p8_zvfbfwma0p8_zvfh0p1_sscofpmf_sstc_svinval_svnapot_svpbmt";
			riscv,cbom-block-size = <64>;
			riscv,cboz-block-size = <64>;
			mmu-type = "riscv,sv48";
			cpu54_intc: interrupt-controller {
				#interrupt-cells = <1>;
				compatible = "riscv,cpu-intc";
				interrupt-controller;
			};
		};
		cpu@55 {
			device_type = "cpu";
			reg = <55>;
			status = "okay";
			compatible = "riscv";
			riscv,isa = "rv64imafdcv_zicbom_zicbop_zicboz_zicond1p0_zihintntl0p2_zihintpause_zawrs_zfa0p1_zfbfmin0p8_zfh_zca_zcb_zcd_zba_zbb_zbc_zbs_zvfbfmin0p8_zvfbfwma0p8_zvfh0p1_sscofpmf_sstc_svinval_svnapot_svpbmt";
			riscv,cbom-block-size = <64>;
			riscv,cboz-block-size = <64>;
			mmu-type = "riscv,sv48";
			cpu55_intc: interrupt-controller {
				#interrupt-cells = <1>;
				compatible = "riscv,cpu-intc";
				interrupt-controller;
			};
		};
		cpu@56 {
			device_type = "cpu";
			reg = <56>;
			status = "okay";
			compatible = "riscv";
			riscv,isa = "rv64imafdcv_zicbom_zicbop_zicboz_zicond1p0_zihintntl0p2_zihintpause_zawrs_zfa0p1_zfbfmin0p8_zfh_zca_zcb_zcd_zba_zbb_zbc_zbs_zvfbfmin0p8_zvfbfwma0p8_zvfh0p1_sscofpmf_sstc_svinval_svnapot_svpbmt";
			riscv,cbom-block-size = <64>;
			riscv,cboz-block-size = <64>;
			mmu-type = "riscv,sv48";
			cpu56_intc: interrupt-controller {
				#interrupt-cells = <1>;
				compatible = "riscv,cpu-intc";
				interrupt-controller;
			};
		};
		cpu@57 {
			device_type = "cpu";
			reg = <57>;
			status = "okay";
			compatible = "riscv";
			riscv,isa = "rv64imafdcv_zicbom_zicbop_zicboz_zicond1p0_zihintntl0p2_zihintpause_zawrs_zfa0p1_zfbfmin0p8_zfh_zca_zcb_zcd_zba_zbb_zbc_zbs_zvfbfmin0p8_zvfbfwma0p8_zvfh0p1_sscofpmf_sstc_svinval_svnapot_svpbmt";
			riscv,cbom-block-size = <64>;
			riscv,cboz-block-size = <64>;
			mmu-type = "riscv,sv48";
			cpu57_intc: interrupt-controller {
				#interrupt-cells = <1>;
				compatible = "riscv,cpu-intc";
				interrupt-controller;
			};
		};
		cpu@58 {
			device_type = "cpu";
			reg = <58>;
			status = "okay";
			compatible = "riscv";
			riscv,isa = "rv64imafdcv_zicbom_zicbop_zicboz_zicond1p0_zihintntl0p2_zihintpause_zawrs_zfa0p1_zfbfmin0p8_zfh_zca_zcb_zcd_zba_zbb_zbc_zbs_zvfbfmin0p8_zvfbfwma0p8_zvfh0p1_sscofpmf_sstc_svinval_svnapot_svpbmt";
			riscv,cbom-block-size = <64>;
			riscv,cboz-block-size = <64>;
			mmu-type = "riscv,sv48";
			cpu58_intc: interrupt-controller {
				#interrupt-cells = <1>;
				compatible = "riscv,cpu-intc";
				interrupt-controller;
			};
		};
		cpu@59 {
			device_type = "cpu";
			reg = <59>;
			status = "okay";
			compatible = "riscv";
			riscv,isa = "rv64imafdcv_zicbom_zicbop_zicboz_zicond1p0_zihintntl0p2_zihintpause_zawrs_zfa0p1_zfbfmin0p8_zfh_zca_zcb_zcd_zba_zbb_zbc_zbs_zvfbfmin0p8_zvfbfwma0p8_zvfh0p1_sscofpmf_sstc_svinval_svnapot_svpbmt";
			riscv,cbom-block-size = <64>;
			riscv,cboz-block-size = <64>;
			mmu-type = "riscv,sv48";
			cpu59_intc: interrupt-controller {
				#interrupt-cells = <1>;
				compatible = "riscv,cpu-intc";
				interrupt-controller;
			};
		};
		cpu@60 {
			device_type = "cpu";
			reg = <60>;
			status = "okay";
			compatible = "riscv";
			riscv,isa = "rv64imafdcv_zicbom_zicbop_zicboz_zicond1p0_zihintntl0p2_zihintpause_zawrs_zfa0p1_zfbfmin0p8_zfh_zca_zcb_zcd_zba_zbb_zbc_zbs_zvfbfmin0p8_zvfbfwma0p8_zvfh0p1_sscofpmf_sstc_svinval_svnapot_svpbmt";
			riscv,cbom-block-size = <64>;
			riscv,cboz-block-size = <64>;
			mmu-type = "riscv,sv48";
			cpu60_intc: interrupt-controller {
				#interrupt-cells = <1>;
				compatible = "riscv,cpu-intc";
				interrupt-controller;
			};
		};
		cpu@61 {
			device_type = "cpu";
			reg = <61>;
			status = "okay";
			compatible = "riscv";
			riscv,isa = "rv64imafdcv_zicbom_zicbop_zicboz_zicond1p0_zihintntl0p2_zihintpause_zawrs_zfa0p1_zfbfmin0p8_zfh_zca_zcb_zcd_zba_zbb_zbc_zbs_zvfbfmin0p8_zvfbfwma0p8_zvfh0p1_sscofpmf_sstc_svinval_svnapot_svpbmt";
			riscv,cbom-block-size = <64>;
			riscv,cboz-block-size = <64>;
			mmu-type = "riscv,sv48";
			cpu61_intc: interrupt-controller {
				#interrupt-cells = <1>;
				compatible = "riscv,cpu-intc";
				interrupt-controller;
			};
		};
		cpu@62 {
			device_type = "cpu";
			reg = <62>;
			status = "okay";
			compatible = "riscv";
			riscv,isa = "rv64imafdcv_zicbom_zicbop_zicboz_zicond1p0_zihintntl0p2_zihintpause_zawrs_zfa0p1_zfbfmin0p8_zfh_zca_zcb_zcd_zba_zbb_zbc_zbs_zvfbfmin0p8_zvfbfwma0p8_zvfh0p1_sscofpmf_sstc_svinval_svnapot_svpbmt";
			riscv,cbom-block-size = <64>;
			riscv,cboz-block-size = <64>;
			mmu-type = "riscv,sv48";
			cpu62_intc: interrupt-controller {
				#interrupt-cells = <1>;
				compatible = "riscv,cpu-intc";
				interrupt-controller;
			};
		};
		cpu@63 {
			device_type = "cpu";
			reg = <63>;
			status = "okay";
			compatible = "riscv";
			riscv,isa = "rv64imafdcv_zicbom_zicbop_zicboz_zicond1p0_zihintntl0p2_zihintpause_zawrs_zfa0p1_zfbfmin0p8_zfh_zca_zcb_zcd_zba_zbb_zbc_zbs_zvfbfmin0p8_zvfbfwma0p8_zvfh0p1_sscofpmf_sstc_svinval_svnapot_svpbmt";
			riscv,cbom-block-size = <64>;
			riscv,cboz-block-size = <64>;
			mmu-type = "riscv,sv48";
			cpu63_intc: interrupt-controller {
				#interrupt-cells = <1>;
				compatible = "riscv,cpu-intc";
				interrupt-controller;
			};
		};
	};

	pmu {
		compatible = "riscv,pmu";
		riscv,event-to-mhpmevent =
			<0x00003 0x00000000 0x00000010>,
			<0x00004 0x00000000 0x00000011>,
			<0x00005 0x00000000 0x00000007>,
			<0x00006 0x00000000 0x00000006>,
			<0x00008 0x00000000 0x00000027>,
			<0x00009 0x00000000 0x00000028>,
			<0x10000 0x00000000 0x0000000c>,
			<0x10001 0x00000000 0x0000000d>,
			<0x10002 0x00000000 0x0000000e>,
			<0x10003 0x00000000 0x0000000f>,
			<0x10008 0x00000000 0x00000001>,
			<0x10009 0x00000000 0x00000002>,
			<0x10010 0x00000000 0x00000010>,
			<0x10011 0x00000000 0x00000011>,
			<0x10012 0x00000000 0x00000012>,
			<0x10013 0x00000000 0x00000013>,
			<0x10019 0x00000000 0x00000004>,
			<0x10021 0x00000000 0x00000003>,
			<0x10030 0x00000000 0x0000001c>,
			<0x10031 0x00000000 0x0000001b>;
		riscv,event-to-mhpmcounters =
			<0x00003 0x00003 0xfffffff8>,
			<0x00004 0x00004 0xfffffff8>,
			<0x00005 0x00005 0xfffffff8>,
			<0x00006 0x00006 0xfffffff8>,
			<0x00007 0x00007 0xfffffff8>,
			<0x00008 0x00008 0xfffffff8>,
			<0x00009 0x00009 0xfffffff8>,
			<0x0000a 0x0000a 0xfffffff8>,
			<0x10000 0x10000 0xfffffff8>,
			<0x10001 0x10001 0xfffffff8>,
			<0x10002 0x10002 0xfffffff8>,
			<0x10003 0x10003 0xfffffff8>,
			<0x10008 0x10008 0xfffffff8>,
			<0x10009 0x10009 0xfffffff8>,
			<0x10010 0x10010 0xfffffff8>,
			<0x10011 0x10011 0xfffffff8>,
			<0x10012 0x10012 0xfffffff8>,
			<0x10013 0x10013 0xfffffff8>,
			<0x10019 0x10019 0xfffffff8>,
			<0x10021 0x10021 0xfffffff8>,
			<0x10030 0x10030 0xfffffff8>,
			<0x10031 0x10031 0xfffffff8>;
		riscv,raw-event-to-mhpmcounters =
			<0x00000000 0x00000001 0xffffffff 0xffffffff 0xfffffff8>,
			<0x00000000 0x00000002 0xffffffff 0xffffffff 0xfffffff8>,
			<0x00000000 0x00000003 0xffffffff 0xffffffff 0xfffffff8>,
			<0x00000000 0x00000004 0xffffffff 0xffffffff 0xfffffff8>,
			<0x00000000 0x00000005 0xffffffff 0xffffffff 0xfffffff8>,
			<0x00000000 0x00000006 0xffffffff 0xffffffff 0xfffffff8>,
			<0x00000000 0x00000007 0xffffffff 0xffffffff 0xfffffff8>,
			<0x00000000 0x00000008 0xffffffff 0xffffffff 0xfffffff8>,
			<0x00000000 0x00000009 0xffffffff 0xffffffff 0xfffffff8>,
			<0x00000000 0x0000000a 0xffffffff 0xffffffff 0xfffffff8>,
			<0x00000000 0x0000000b 0xffffffff 0xffffffff 0xfffffff8>,
			<0x00000000 0x0000000c 0xffffffff 0xffffffff 0xfffffff8>,
			<0x00000000 0x0000000d 0xffffffff 0xffffffff 0xfffffff8>,
			<0x00000000 0x0000000e 0xffffffff 0xffffffff 0xfffffff8>,
			<0x00000000 0x0000000f 0xffffffff 0xffffffff 0xfffffff8>,
			<0x00000000 0x00000010 0xffffffff 0xffffffff 0xfffffff8>,
			<0x00000000 0x00000011 0xffffffff 0xffffffff 0xfffffff8>,
			<0x00000000 0x00000012 0xffffffff 0xffffffff 0xfffffff8>,
			<0x00000000 0x00000013 0xffffffff 0xffffffff 0xfffffff8>,
			<0x00000000 0x00000014 0xffffffff 0xffffffff 0xfffffff8>,
			<0x00000000 0x00000015 0xffffffff 0xffffffff 0xfffffff8>,
			<0x00000000 0x00000016 0xffffffff 0xffffffff 0xfffffff8>,
			<0x00000000 0x00000017 0xffffffff 0xffffffff 0xfffffff8>,
			<0x00000000 0x00000018 0xffffffff 0xffffffff 0xfffffff8>,
			<0x00000000 0x00000019 0xffffffff 0xffffffff 0xfffffff8>,
			<0x00000000 0x0000001a 0xffffffff 0xffffffff 0xfffffff8>,
			<0x00000000 0x0000001b 0xffffffff 0xffffffff 0xfffffff8>,
			<0x00000000 0x0000001c 0xffffffff 0xffffffff 0xfffffff8>,
			<0x00000000 0x0000001d 0xffffffff 0xffffffff 0xfffffff8>,
			<0x00000000 0x0000001e 0xffffffff 0xffffffff 0xfffffff8>,
			<0x00000000 0x0000001f 0xffffffff 0xffffffff 0xfffffff8>,
			<0x00000000 0x00000020 0xffffffff 0xffffffff 0xfffffff8>,
			<0x00000000 0x00000021 0xffffffff 0xffffffff 0xfffffff8>,
			<0x00000000 0x00000022 0xffffffff 0xffffffff 0xfffffff8>,
			<0x00000000 0x00000023 0xffffffff 0xffffffff 0xfffffff8>,
			<0x00000000 0x00000024 0xffffffff 0xffffffff 0xfffffff8>,
			<0x00000000 0x00000025 0xffffffff 0xffffffff 0xfffffff8>,
			<0x00000000 0x00000026 0xffffffff 0xffffffff 0xfffffff8>,
			<0x00000000 0x00000027 0xffffffff 0xffffffff 0xfffffff8>,
			<0x00000000 0x00000028 0xffffffff 0xffffffff 0xfffffff8>,
			<0x00000000 0x00000029 0xffffffff 0xffffffff 0xfffffff8>,
			<0x00000000 0x0000002a 0xffffffff 0xffffffff 0xfffffff8>;
	};

	rst: reset-controller {
		#reset-cells = <1>;
		compatible = "sophgo,reset";
		subctrl-syscon = <&top_misc>;
		top_rst_offset = <0x3000>;
		nr_resets = <RST_MAX_NUM>;
	};

	soc {
		#address-cells = <2>;
		#size-cells = <2>;
		compatible = "simple-bus";
		ranges;

		clint_mswi: interrupt-controller@6d44000000 {
			compatible = "thead,c900-clint-mswi";
			reg = <0x0000006d 0x44000000 0x00000000 0x00004000>;
			interrupts-extended = <&cpu0_intc  3>,
					      <&cpu1_intc  3>,
					      <&cpu2_intc  3>,
					      <&cpu3_intc  3>,
					      <&cpu4_intc  3>,
					      <&cpu5_intc  3>,
					      <&cpu6_intc  3>,
					      <&cpu7_intc  3>,
					      <&cpu8_intc  3>,
					      <&cpu9_intc  3>,
					      <&cpu10_intc 3>,
					      <&cpu11_intc 3>,
					      <&cpu12_intc 3>,
					      <&cpu13_intc 3>,
					      <&cpu14_intc 3>,
					      <&cpu15_intc 3>,
					      <&cpu16_intc 3>,
					      <&cpu17_intc 3>,
					      <&cpu18_intc 3>,
					      <&cpu19_intc 3>,
					      <&cpu20_intc 3>,
					      <&cpu21_intc 3>,
					      <&cpu22_intc 3>,
					      <&cpu23_intc 3>,
					      <&cpu24_intc 3>,
					      <&cpu25_intc 3>,
					      <&cpu26_intc 3>,
					      <&cpu27_intc 3>,
					      <&cpu28_intc 3>,
					      <&cpu29_intc 3>,
					      <&cpu30_intc 3>,
					      <&cpu31_intc 3>,
					      <&cpu32_intc 3>,
					      <&cpu33_intc 3>,
					      <&cpu34_intc 3>,
					      <&cpu35_intc 3>,
					      <&cpu36_intc 3>,
					      <&cpu37_intc 3>,
					      <&cpu38_intc 3>,
					      <&cpu39_intc 3>,
					      <&cpu40_intc 3>,
					      <&cpu41_intc 3>,
					      <&cpu42_intc 3>,
					      <&cpu43_intc 3>,
					      <&cpu44_intc 3>,
					      <&cpu45_intc 3>,
					      <&cpu46_intc 3>,
					      <&cpu47_intc 3>,
					      <&cpu48_intc 3>,
					      <&cpu49_intc 3>,
					      <&cpu50_intc 3>,
					      <&cpu51_intc 3>,
					      <&cpu52_intc 3>,
					      <&cpu53_intc 3>,
					      <&cpu54_intc 3>,
					      <&cpu55_intc 3>,
					      <&cpu56_intc 3>,
					      <&cpu57_intc 3>,
					      <&cpu58_intc 3>,
					      <&cpu59_intc 3>,
					      <&cpu60_intc 3>,
					      <&cpu61_intc 3>,
					      <&cpu62_intc 3>,
					      <&cpu63_intc 3>;
		};

		clint_mtimer: timer@6840000000 {
			compatible = "thead,c900-clint-mtimer";
			reg = <0x00000068 0x40000000 0x00000000 0x00008000>;
			interrupts-extended = <&cpu0_intc  7>,
					      <&cpu1_intc  7>,
					      <&cpu2_intc  7>,
					      <&cpu3_intc  7>,
					      <&cpu4_intc  7>,
					      <&cpu5_intc  7>,
					      <&cpu6_intc  7>,
					      <&cpu7_intc  7>,
					      <&cpu8_intc  7>,
					      <&cpu9_intc  7>,
					      <&cpu10_intc 7>,
					      <&cpu11_intc 7>,
					      <&cpu12_intc 7>,
					      <&cpu13_intc 7>,
					      <&cpu14_intc 7>,
					      <&cpu15_intc 7>,
					      <&cpu16_intc 7>,
					      <&cpu17_intc 7>,
					      <&cpu18_intc 7>,
					      <&cpu19_intc 7>,
					      <&cpu20_intc 7>,
					      <&cpu21_intc 7>,
					      <&cpu22_intc 7>,
					      <&cpu23_intc 7>,
					      <&cpu24_intc 7>,
					      <&cpu25_intc 7>,
					      <&cpu26_intc 7>,
					      <&cpu27_intc 7>,
					      <&cpu28_intc 7>,
					      <&cpu29_intc 7>,
					      <&cpu30_intc 7>,
					      <&cpu31_intc 7>,
					      <&cpu32_intc 7>,
					      <&cpu33_intc 7>,
					      <&cpu34_intc 7>,
					      <&cpu35_intc 7>,
					      <&cpu36_intc 7>,
					      <&cpu37_intc 7>,
					      <&cpu38_intc 7>,
					      <&cpu39_intc 7>,
					      <&cpu40_intc 7>,
					      <&cpu41_intc 7>,
					      <&cpu42_intc 7>,
					      <&cpu43_intc 7>,
					      <&cpu44_intc 7>,
					      <&cpu45_intc 7>,
					      <&cpu46_intc 7>,
					      <&cpu47_intc 7>,
					      <&cpu48_intc 7>,
					      <&cpu49_intc 7>,
					      <&cpu50_intc 7>,
					      <&cpu51_intc 7>,
					      <&cpu52_intc 7>,
					      <&cpu53_intc 7>,
					      <&cpu54_intc 7>,
					      <&cpu55_intc 7>,
					      <&cpu56_intc 7>,
					      <&cpu57_intc 7>,
					      <&cpu58_intc 7>,
					      <&cpu59_intc 7>,
					      <&cpu60_intc 7>,
					      <&cpu61_intc 7>,
					      <&cpu62_intc 7>,
					      <&cpu63_intc 7>;
		};

		intc: interrupt-controller@6d40000000 {
			compatible = "thead,c900-plic";
			#address-cells = <0>;
			#interrupt-cells = <2>;
			reg = <0x0000006d 0x40000000 0x00000000 0x10000000>;
			riscv,ndev = <863>;
			interrupt-controller;
			interrupts-extended = <&cpu0_intc   11>, < &cpu0_intc   9>,
					      <&cpu1_intc   11>, < &cpu1_intc   9>,
					      <&cpu2_intc   11>, < &cpu2_intc   9>,
					      <&cpu3_intc   11>, < &cpu3_intc   9>,
					      <&cpu4_intc   11>, < &cpu4_intc   9>,
					      <&cpu5_intc   11>, < &cpu5_intc   9>,
					      <&cpu6_intc   11>, < &cpu6_intc   9>,
					      <&cpu7_intc   11>, < &cpu7_intc   9>,
					      <&cpu8_intc   11>, < &cpu8_intc   9>,
					      <&cpu9_intc   11>, < &cpu9_intc   9>,
					      <&cpu10_intc  11>, < &cpu10_intc  9>,
					      <&cpu11_intc  11>, < &cpu11_intc  9>,
					      <&cpu12_intc  11>, < &cpu12_intc  9>,
					      <&cpu13_intc  11>, < &cpu13_intc  9>,
					      <&cpu14_intc  11>, < &cpu14_intc  9>,
					      <&cpu15_intc  11>, < &cpu15_intc  9>,
					      <&cpu16_intc  11>, < &cpu16_intc  9>,
					      <&cpu17_intc  11>, < &cpu17_intc  9>,
					      <&cpu18_intc  11>, < &cpu18_intc  9>,
					      <&cpu19_intc  11>, < &cpu19_intc  9>,
					      <&cpu20_intc  11>, < &cpu20_intc  9>,
					      <&cpu21_intc  11>, < &cpu21_intc  9>,
					      <&cpu22_intc  11>, < &cpu22_intc  9>,
					      <&cpu23_intc  11>, < &cpu23_intc  9>,
					      <&cpu24_intc  11>, < &cpu24_intc  9>,
					      <&cpu25_intc  11>, < &cpu25_intc  9>,
					      <&cpu26_intc  11>, < &cpu26_intc  9>,
					      <&cpu27_intc  11>, < &cpu27_intc  9>,
					      <&cpu28_intc  11>, < &cpu28_intc  9>,
					      <&cpu29_intc  11>, < &cpu29_intc  9>,
					      <&cpu30_intc  11>, < &cpu30_intc  9>,
					      <&cpu31_intc  11>, < &cpu31_intc  9>,
					      <&cpu32_intc  11>, < &cpu32_intc  9>,
					      <&cpu33_intc  11>, < &cpu33_intc  9>,
					      <&cpu34_intc  11>, < &cpu34_intc  9>,
					      <&cpu35_intc  11>, < &cpu35_intc  9>,
					      <&cpu36_intc  11>, < &cpu36_intc  9>,
					      <&cpu37_intc  11>, < &cpu37_intc  9>,
					      <&cpu38_intc  11>, < &cpu38_intc  9>,
					      <&cpu39_intc  11>, < &cpu39_intc  9>,
					      <&cpu40_intc  11>, < &cpu40_intc  9>,
					      <&cpu41_intc  11>, < &cpu41_intc  9>,
					      <&cpu42_intc  11>, < &cpu42_intc  9>,
					      <&cpu43_intc  11>, < &cpu43_intc  9>,
					      <&cpu44_intc  11>, < &cpu44_intc  9>,
					      <&cpu45_intc  11>, < &cpu45_intc  9>,
					      <&cpu46_intc  11>, < &cpu46_intc  9>,
					      <&cpu47_intc  11>, < &cpu47_intc  9>,
					      <&cpu48_intc  11>, < &cpu48_intc  9>,
					      <&cpu49_intc  11>, < &cpu49_intc  9>,
					      <&cpu50_intc  11>, < &cpu50_intc  9>,
					      <&cpu51_intc  11>, < &cpu51_intc  9>,
					      <&cpu52_intc  11>, < &cpu52_intc  9>,
					      <&cpu53_intc  11>, < &cpu53_intc  9>,
					      <&cpu54_intc  11>, < &cpu54_intc  9>,
					      <&cpu55_intc  11>, < &cpu55_intc  9>,
					      <&cpu56_intc  11>, < &cpu56_intc  9>,
					      <&cpu57_intc  11>, < &cpu57_intc  9>,
					      <&cpu58_intc  11>, < &cpu58_intc  9>,
					      <&cpu59_intc  11>, < &cpu59_intc  9>,
					      <&cpu60_intc  11>, < &cpu60_intc  9>,
					      <&cpu61_intc  11>, < &cpu61_intc  9>,
					      <&cpu62_intc  11>, < &cpu62_intc  9>,
					      <&cpu63_intc  11>, < &cpu63_intc  9>;
		};

		uart0: serial@7030001000 {
			compatible = "snps,dw-apb-uart";
			reg = <0x00000070 0x30001000 0x00000000 0x00001000>;
			interrupt-parent = <&intc>;
			interrupts = <42 IRQ_TYPE_LEVEL_HIGH>;
			clock-frequency = <500000000>;
			clocks = <&div_clk GATE_CLK_UART_500M>,
					 <&div_clk GATE_CLK_APB_UART>;
			clock-names = "baudclk", "apb_pclk";
			current-speed = <115200>;
			reg-shift = <2>;
			reg-io-width = <4>;
		};

		emmc: bm-emmc@703000A000 {
			compatible = "bitmain,bm-emmc";
			reg = <0x70 0x3000A000 0x0 0x1000>;
			reg-names = "core_mem";
			interrupt-parent = <&intc>;
			interrupts = <298 IRQ_TYPE_LEVEL_HIGH>;
			bus-width = <4>;
			non-removable;
			no-sdio;
			no-sd;
			resets = <&rst SG2044_RST_EMMC>;
			reset-names = "emmc";
			clocks =
				<&div_clk GATE_CLK_EMMC>,
				<&div_clk GATE_CLK_AXI_EMMC>,
				<&div_clk GATE_CLK_100K_EMMC>;
			clock-names =
				"clk_gate_emmc",
				"clk_gate_axi_emmc",
				"clk_gate_100k_emmc";
		};

		sd: bm-sd@703000B000 {
			compatible = "bitmain,bm-sd";
			reg = <0x70 0x3000B000 0x0 0x1000>;
			reg-names = "core_mem";
			interrupt-parent = <&intc>;
			interrupts = <300 IRQ_TYPE_LEVEL_HIGH>;
			bus-width = <4>;
			no-sdio;
			no-mmc;
			resets = <&rst SG2044_RST_SD>;
			reset-names = "sdio";
			clocks =
				<&div_clk GATE_CLK_SD>,
				<&div_clk GATE_CLK_AXI_SD>,
				<&div_clk GATE_CLK_100K_SD>;
			clock-names =
				"clk_gate_sd",
				"clk_gate_axi_sd",
				"clk_gate_100k_sd";
		};

		gpio0: gpio@7040009000 {
			compatible = "snps,dw-apb-gpio";
			reg = <0x70 0x40009000 0x0 0x400>;
			#address-cells = <1>;
			#size-cells = <0>;
			clocks = <&div_clk GATE_CLK_APB_GPIO>,
				 <&div_clk GATE_CLK_APB_GPIO_INTR>,
				 <&div_clk GATE_CLK_GPIO_DB>;
			clock-names = "base_clk", "intr_clk", "db_clk";

			port0a: gpio-controller@0 {
				compatible = "snps,dw-apb-gpio-port";
				bank-name = "port0a";
				gpio-controller;
				#gpio-cells = <2>;
				snps,nr-gpios = <32>;
				reg = <0>;
				interrupt-controller;
				#interrupt-cells = <2>;
				interrupt-parent = <&intc>;
				interrupts = <26 IRQ_TYPE_LEVEL_HIGH>;
			};
		};

		gpio1: gpio@704000a000 {
			compatible = "snps,dw-apb-gpio";
			reg = <0x70 0x4000a000 0x0 0x400>;
			#address-cells = <1>;
			#size-cells = <0>;

			clocks = <&div_clk GATE_CLK_APB_GPIO>,
				 <&div_clk GATE_CLK_APB_GPIO_INTR>,
				 <&div_clk GATE_CLK_GPIO_DB>;
			clock-names = "base_clk", "intr_clk", "db_clk";

			port1a: gpio-controller@0 {
				compatible = "snps,dw-apb-gpio-port";
				bank-name = "port0a";
				gpio-controller;
				#gpio-cells = <2>;
				snps,nr-gpios = <32>;
				reg = <0>;
				interrupt-controller;
				#interrupt-cells = <2>;
				interrupt-parent = <&intc>;
				interrupts = <27 IRQ_TYPE_LEVEL_HIGH>;
			};
		};

		gpio2: gpio@704000b000 {
			compatible = "snps,dw-apb-gpio";
			reg = <0x70 0x4000b000 0x0 0x400>;
			#address-cells = <1>;
			#size-cells = <0>;
			clocks = <&div_clk GATE_CLK_APB_GPIO>,
				 <&div_clk GATE_CLK_APB_GPIO_INTR>,
				 <&div_clk GATE_CLK_GPIO_DB>;
			clock-names = "base_clk", "intr_clk", "db_clk";

			port2a: gpio-controller@0 {
				compatible = "snps,dw-apb-gpio-port";
				bank-name = "port0a";
				gpio-controller;
				#gpio-cells = <2>;
				snps,nr-gpios = <32>;
				reg = <0>;
				interrupt-controller;
				#interrupt-cells = <2>;
				interrupt-parent = <&intc>;
				interrupts = <28 IRQ_TYPE_LEVEL_HIGH>;
			};
		};

		stmmac_axi_setup: stmmac-axi-config {
			snps,wr_osr_lmt = <1>;
			snps,rd_osr_lmt = <2>;
			snps,blen = <4 8 16 0 0 0 0>;
		};

		mtl_rx_setup: rx-queues-config {
			snps,rx-queues-to-use = <8>;
			queue0 {snps,rx-sched-wsp;};
			queue1 {snps,rx-sched-wsp;};
			queue2 {snps,rx-sched-wsp;};
			queue3 {snps,rx-sched-wsp;};
			queue4 {snps,rx-sched-wsp;};
			queue5 {snps,rx-sched-wsp;};
			queue6 {snps,rx-sched-wsp;};
			queue7 {snps,rx-sched-wsp;};
		};

		mtl_tx_setup: tx-queues-config {
			snps,tx-queues-to-use = <8>;
			queue0 {};
			queue1 {};
			queue2 {};
			queue3 {};
			queue4 {};
			queue5 {};
			queue6 {};
			queue7 {};
		};

		ethernet0: ethernet@7030006000 {
			compatible = "sophgo,ethernet";
			reg = <0x70 0x30006000 0x0 0x4000>;
			interrupt-names = "macirq";
			interrupt-parent = <&intc>;
			interrupts = <296 IRQ_TYPE_LEVEL_HIGH>;
			clock-names = "clk_tx", "gate_clk_tx", "stmmaceth", "ptp_ref", "gate_clk_ref";
			clocks = <&div_clk DIV_CLK_FPLL0_TX_ETH0>,
				<&div_clk GATE_CLK_TX_ETH0>,
				<&div_clk GATE_CLK_AXI_ETH0>,
				<&div_clk DIV_CLK_FPLL0_PTP_REF_I_ETH0>,
				<&div_clk GATE_CLK_REF_ETH0>;
			/* no hash filter and perfect filter support */
			snps,multicast-filter-bins = <0>;
			snps,perfect-filter-entries = <1>;

			snps,txpbl = <32>;
			snps,rxpbl = <32>;
			snps,aal;
			snps,tso;

			snps,axi-config = <&stmmac_axi_setup>;
			snps,mtl-rx-config = <&mtl_rx_setup>;
			snps,mtl-tx-config = <&mtl_tx_setup>;

			sophgo,gmac;

			phy-mode = "rgmii-id";
			phy-reset-gpios = <&port0a 28 0>;
		};

		p2p: p2p {
			compatible = "sophgon, p2p";
			reg = <0x0000006c 0x08790000 0x00000000 0x000010000>,
			      <0x0000006c 0x087D0000 0x00000000 0x000010000>;
			reg-names = "cdma_cfg","cxp_top_cfg";
			interrupt-parent = <&intc>;
			interrupts = <127 IRQ_TYPE_LEVEL_HIGH>;
			interrupt-names = "CXP_CDMA0";
		};

		base {
			compatible = "sophon,base";
		};

		// video & jpeg
		vc_drv {
		      #interrupt-cells = <1>;
		      compatible = "sophgo,vc_drv";
		      reg = <0x6b 0x00180000 0x0 0x10000>,
			    <0x6b 0x00190000 0x0 0x10000>,
			    <0x6b 0x001a0000 0x0 0x10000>,
			    <0x6b 0x001b0000 0x0 0x10000>,
			    <0x6b 0x02180000 0x0 0x10000>,
			    <0x6b 0x02190000 0x0 0x10000>,
			    <0x6b 0x021a0000 0x0 0x10000>,
			    <0x6b 0x021b0000 0x0 0x10000>,
			    <0x6b 0x04180000 0x0 0x10000>,
			    <0x6b 0x04190000 0x0 0x10000>,
			    <0x6b 0x041a0000 0x0 0x10000>,
			    <0x6b 0x041b0000 0x0 0x10000>,
			    <0x6b 0x06180000 0x0 0x10000>,
			    <0x6b 0x06190000 0x0 0x10000>,
			    <0x6b 0x061a0000 0x0 0x10000>,
			    <0x6b 0x061b0000 0x0 0x10000>,
			    <0x00 0x00010000 0x0 0x10000>,
			    <0x00 0x00020000 0x0 0x10000>,
			    <0x00 0x02010000 0x0 0x10000>,
			    <0x00 0x02020000 0x0 0x10000>,
			    <0x00 0x04010000 0x0 0x10000>,
			    <0x00 0x04020000 0x0 0x10000>,
			    <0x00 0x06010000 0x0 0x10000>,
			    <0x00 0x06020000 0x0 0x10000>,
			    <0x6b 0x00040000 0x0 0x10000>,
			    <0x6b 0x00042000 0x0 0x10000>,
			    <0x6b 0x02040000 0x0 0x10000>,
			    <0x6b 0x02042000 0x0 0x10000>,
			    <0x6b 0x04040000 0x0 0x10000>,
			    <0x6b 0x04042000 0x0 0x10000>,
			    <0x6b 0x06040000 0x0 0x10000>,
			    <0x6b 0x06042000 0x0 0x10000>;

			    interrupt-parent = <&intc>;
			    interrupts = <161 162 167 168 201 202 207 208
					  241 242 247 248 281 282 287 288
					  136 140 176 180 216 220 256 260
					  137 141 177 181 217 221 257 261
					  138 142 178 182 218 222 258 262
					  139 143 179 183 219 223 259 263
					  148 149 188 189 228 229 267 268>;
		};

		vpss {
			#interrupt-cells = <1>;
			compatible = "sophgo,vpss";
			reg = <0x0000006B 0x00100000 0x00000000 0x0007FFFF>,
			      <0x0000006B 0x02100000 0x00000000 0x0007FFFF>,
			      <0x0000006B 0x04100000 0x00000000 0x0007FFFF>,
			      <0x0000006B 0x06100000 0x00000000 0x0007FFFF>;

			interrupt-parent = <&intc>;
			interrupts = <157 158 159 160 163 164 165 166
				      197 198 199 200 203 204 205 206
				      237 238 239 240 243 244 245 246
				      277 278 279 280 283 284 285 286>;
		};

		sg2260_host_driver@0 {
			compatible = "sophgo,sg2260_host_driver";
			chip_type = <0x1690>;
			interrupt-parent = <&intc>;
			interrupts = <352 IRQ_TYPE_LEVEL_HIGH>;
		};
	};

	aliases {
		serial0 = &uart0;
	};

	chosen {
		bootargs = "console=ttyS0,115200 earlycon rdinit=/init root=/dev/ram0 rw initrd=0x8b000000,32M no5lvl";
		stdout-path = "serial0";
	};
};
//#include "sg2260-pcie-intc-rp.dtsi"
//#include "sg2260-pcie-5rc-rp.dtsi"
